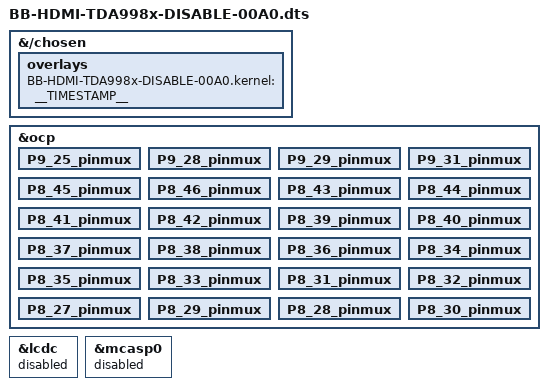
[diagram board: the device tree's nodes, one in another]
// SPDX-License-Identifier: GPL-2.0-only
/*
 * Copyright (C) 2012 Texas Instruments Incorporated - https://www.ti.com/
 */

/dts-v1/;
/plugin/;

#include <dt-bindings/gpio/gpio.h>
#include <dt-bindings/pinctrl/am33xx.h>
#include <dt-bindings/display/tda998x.h>
#include <dt-bindings/interrupt-controller/irq.h>

/*
 * Helper to show loaded overlays under: /proc/device-tree/chosen/overlays/
 */
&{/chosen} {
	overlays {
		BB-HDMI-TDA998x-DISABLE-00A0.kernel = __TIMESTAMP__;
	};
};

&ocp {
	P9_25_pinmux { status = "okay"; };	/* mcasp0_ahclkx */
	P9_28_pinmux { status = "okay"; };	/* mcasp0_axr2 */
	P9_29_pinmux { status = "okay"; };	/* mcasp0_fsx */
	P9_31_pinmux { status = "okay"; };	/* mcasp0_aclkx */
	P8_45_pinmux { status = "okay"; };	/* lcd_data0 */
	P8_46_pinmux { status = "okay"; };	/* lcd_data1 */
	P8_43_pinmux { status = "okay"; };	/* lcd_data2 */
	P8_44_pinmux { status = "okay"; };	/* lcd_data3 */
	P8_41_pinmux { status = "okay"; };	/* lcd_data4 */
	P8_42_pinmux { status = "okay"; };	/* lcd_data5 */
	P8_39_pinmux { status = "okay"; };	/* lcd_data6 */
	P8_40_pinmux { status = "okay"; };	/* lcd_data7 */
	P8_37_pinmux { status = "okay"; };	/* lcd_data8 */
	P8_38_pinmux { status = "okay"; };	/* lcd_data9 */
	P8_36_pinmux { status = "okay"; };	/* lcd_data10 */
	P8_34_pinmux { status = "okay"; };	/* lcd_data11 */
	P8_35_pinmux { status = "okay"; };	/* lcd_data12 */
	P8_33_pinmux { status = "okay"; };	/* lcd_data13 */
	P8_31_pinmux { status = "okay"; };	/* lcd_data14 */
	P8_32_pinmux { status = "okay"; };	/* lcd_data15 */
	P8_27_pinmux { status = "okay"; };	/* lcd_vsync */
	P8_29_pinmux { status = "okay"; };	/* lcd_hsync */
	P8_28_pinmux { status = "okay"; };	/* lcd_pclk */
	P8_30_pinmux { status = "okay"; };	/* lcd_ac_bias_en */
};

&lcdc {
	status = "disabled";
};

&mcasp0 {
	status = "disabled";
};
